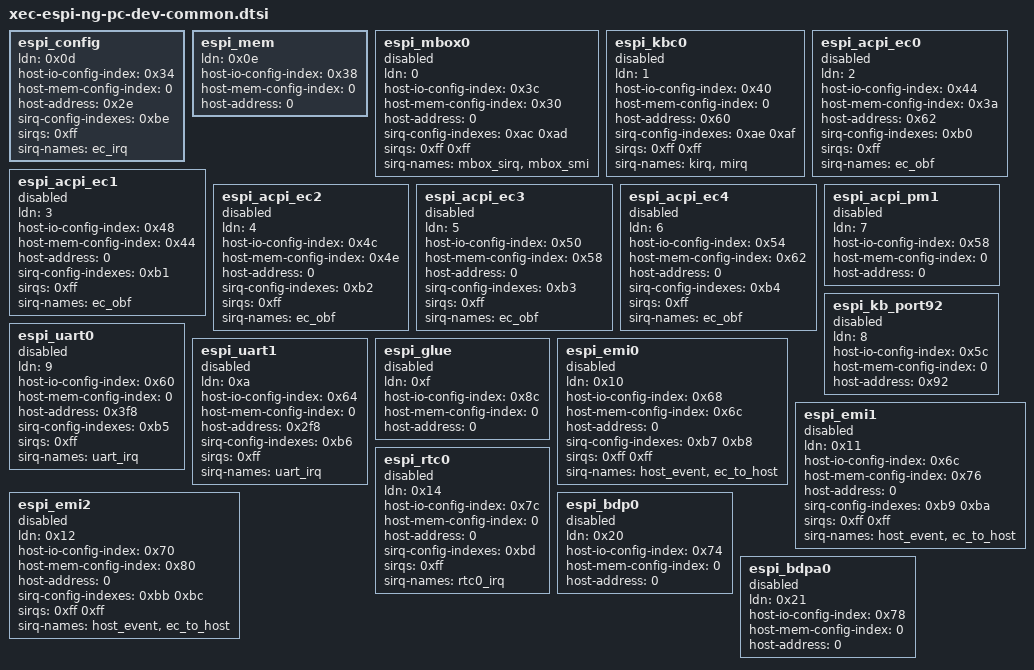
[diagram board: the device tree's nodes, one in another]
/*
 * Copyright (c) 2025 Microchip Technology Inc.
 *
 * SPDX-License-Identifier: Apache-2.0
 */

/* eSPI I/O configuration port */
espi_config: espi_config {
	ldn = <0x0d>;
	host-io-config-index = <0x34>;
	host-mem-config-index = <0>;
	host-address = <0x2e>;
	sirq-config-indexes = <0xbe>;
	sirqs = <0xff>;
	sirq-names = "ec_irq";
	status = "okay";
};
/* eSPI memory component I/O BAR */
espi_mem: espi_mem {
	ldn = <0x0e>;
	host-io-config-index = <0x38>;
	host-mem-config-index = <0>;
	host-address = <0>;
	status = "okay";
};
espi_mbox0: espi_mbox0 {
	ldn = <0>;
	host-io-config-index = <0x3c>;
	host-mem-config-index = <0x30>;
	host-address = <0>;
	sirq-config-indexes = <0xac 0xad>;
	sirqs = <0xff 0xff>;
	sirq-names = "mbox_sirq", "mbox_smi";
	status = "disabled";
};
espi_kbc0: espi_kbc0 {
	ldn = <1>;
	host-io-config-index = <0x40>;
	host-mem-config-index = <0>;
	host-address = <0x60>;
	sirq-config-indexes = <0xae 0xaf>;
	sirqs = <0xff 0xff>;
	sirq-names = "kirq", "mirq";
	status = "disabled";
};
espi_acpi_ec0: espi_acpi_ec0 {
	ldn = <2>;
	host-io-config-index = <0x44>;
	host-mem-config-index = <0x3a>;
	host-address = <0x62>;
	sirq-config-indexes = <0xb0>;
	sirqs = <0xff>;
	sirq-names = "ec_obf";
	status = "disabled";
};
espi_acpi_ec1: espi_acpi_ec1 {
	ldn = <3>;
	host-io-config-index = <0x48>;
	host-mem-config-index = <0x44>;
	host-address = <0>;
	sirq-config-indexes = <0xb1>;
	sirqs = <0xff>;
	sirq-names = "ec_obf";
	status = "disabled";
};
espi_acpi_ec2: espi_acpi_ec2 {
	ldn = <4>;
	host-io-config-index = <0x4c>;
	host-mem-config-index = <0x4e>;
	host-address = <0>;
	sirq-config-indexes = <0xb2>;
	sirqs = <0xff>;
	sirq-names = "ec_obf";
	status = "disabled";
};
espi_acpi_ec3: espi_acpi_ec3 {
	ldn = <5>;
	host-io-config-index = <0x50>;
	host-mem-config-index = <0x58>;
	host-address = <0>;
	sirq-config-indexes = <0xb3>;
	sirqs = <0xff>;
	sirq-names = "ec_obf";
	status = "disabled";
};
espi_acpi_ec4: espi_acpi_ec4 {
	ldn = <6>;
	host-io-config-index = <0x54>;
	host-mem-config-index = <0x62>;
	host-address = <0>;
	sirq-config-indexes = <0xb4>;
	sirqs = <0xff>;
	sirq-names = "ec_obf";
	status = "disabled";
};
espi_acpi_pm1: espi_acpi_pm1 {
	ldn = <7>;
	host-io-config-index = <0x58>;
	host-mem-config-index = <0>;
	host-address = <0>;
	status = "disabled";
};
espi_kb_port92: espi_kb_port92 {
	ldn = <8>;
	host-io-config-index = <0x5c>;
	host-mem-config-index = <0>;
	host-address = <0x92>;
	status = "disabled";
};
espi_uart0: espi_uart0 {
	ldn = <9>;
	host-io-config-index = <0x60>;
	host-mem-config-index = <0>;
	host-address = <0x3f8>;
	sirq-config-indexes = <0xb5>;
	sirqs = <0xff>;
	sirq-names = "uart_irq";
	status = "disabled";
};
espi_uart1: espi_uart1 {
	ldn = <0xa>;
	host-io-config-index = <0x64>;
	host-mem-config-index = <0>;
	host-address = <0x2f8>;
	sirq-config-indexes = <0xb6>;
	sirqs = <0xff>;
	sirq-names = "uart_irq";
	status = "disabled";
};
espi_glue: espi_glue {
	ldn = <0xf>;
	host-io-config-index = <0x8c>;
	host-mem-config-index = <0>;
	host-address = <0>;
	status = "disabled";
};
espi_emi0: espi_emi0 {
	ldn = <0x10>;
	host-io-config-index = <0x68>;
	host-mem-config-index = <0x6c>;
	host-address = <0>;
	sirq-config-indexes = <0xb7 0xb8>;
	sirqs = <0xff 0xff>;
	sirq-names = "host_event", "ec_to_host";
	status = "disabled";
};
espi_emi1: espi_emi1 {
	ldn = <0x11>;
	host-io-config-index = <0x6c>;
	host-mem-config-index = <0x76>;
	host-address = <0>;
	sirq-config-indexes = <0xb9 0xba>;
	sirqs = <0xff 0xff>;
	sirq-names = "host_event", "ec_to_host";
	status = "disabled";
};
espi_emi2: espi_emi2 {
	ldn = <0x12>;
	host-io-config-index = <0x70>;
	host-mem-config-index = <0x80>;
	host-address = <0>;
	sirq-config-indexes = <0xbb 0xbc>;
	sirqs = <0xff 0xff>;
	sirq-names = "host_event", "ec_to_host";
	status = "disabled";
};
espi_rtc0: espi_rtc0 {
	ldn = <0x14>;
	host-io-config-index = <0x7c>;
	host-mem-config-index = <0>;
	host-address = <0>;
	sirq-config-indexes = <0xbd>;
	sirqs = <0xff>;
	sirq-names = "rtc0_irq";
	status = "disabled";
};
espi_bdp0: espi_bdp0 {
	ldn = <0x20>;
	host-io-config-index = <0x74>;
	host-mem-config-index = <0>;
	host-address = <0>;
	status = "disabled";
};
espi_bdpa0: espi_bdpa0 {
	ldn = <0x21>;
	host-io-config-index = <0x78>;
	host-mem-config-index = <0>;
	host-address = <0>;
	status = "disabled";
};
